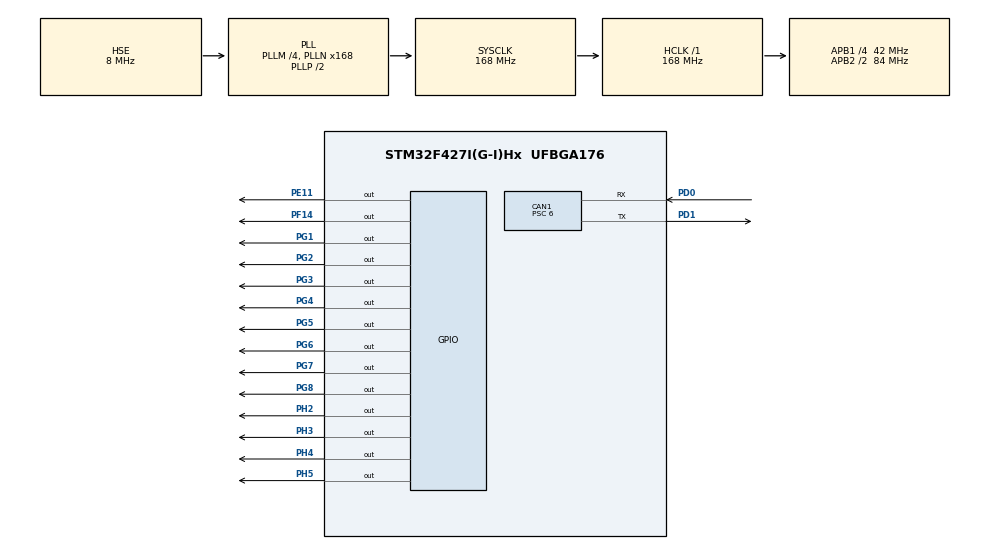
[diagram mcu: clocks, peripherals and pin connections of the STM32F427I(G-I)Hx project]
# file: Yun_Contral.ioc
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CAN1.BS1=CAN_BS1_3TQ
CAN1.BS2=CAN_BS2_3TQ
CAN1.CalculateTimeQuantum=142.85714285714286
CAN1.Prescaler=6
Mcu.Family=STM32F4
Mcu.Name=STM32F427I(G-I)Hx
Mcu.Package=UFBGA176
NVIC.CAN1_RX0_IRQn=true\:5\:0\:true\:false\:true\:true\:true
NVIC.PriorityGroup=NVIC_PRIORITYGROUP_4
PD0.Mode=Master
PD0.Signal=CAN1_RX
PD1.Mode=Master
PD1.Signal=CAN1_TX
PE11.GPIO_PuPd=GPIO_PULLUP
PE11.GPIO_Speed=GPIO_SPEED_FREQ_HIGH
PE11.PinState=GPIO_PIN_SET
PE11.Signal=GPIO_Output
PF14.GPIO_ModeDefaultOutputPP=GPIO_MODE_OUTPUT_PP
PF14.GPIO_PuPd=GPIO_PULLUP
PF14.GPIO_Speed=GPIO_SPEED_FREQ_HIGH
PF14.PinState=GPIO_PIN_SET
PF14.Signal=GPIO_Output
PG1.GPIO_ModeDefaultOutputPP=GPIO_MODE_OUTPUT_PP
PG1.GPIO_PuPd=GPIO_PULLUP
PG1.GPIO_Speed=GPIO_SPEED_FREQ_HIGH
PG1.PinState=GPIO_PIN_SET
PG1.Signal=GPIO_Output
PG2.GPIO_ModeDefaultOutputPP=GPIO_MODE_OUTPUT_PP
PG2.GPIO_PuPd=GPIO_PULLUP
PG2.GPIO_Speed=GPIO_SPEED_FREQ_HIGH
PG2.PinState=GPIO_PIN_SET
PG2.Signal=GPIO_Output
PG3.GPIO_ModeDefaultOutputPP=GPIO_MODE_OUTPUT_PP
PG3.GPIO_PuPd=GPIO_PULLUP
PG3.GPIO_Speed=GPIO_SPEED_FREQ_HIGH
PG3.PinState=GPIO_PIN_SET
PG3.Signal=GPIO_Output
PG4.GPIO_ModeDefaultOutputPP=GPIO_MODE_OUTPUT_PP
PG4.GPIO_PuPd=GPIO_PULLUP
PG4.GPIO_Speed=GPIO_SPEED_FREQ_HIGH
PG4.PinState=GPIO_PIN_SET
PG4.Signal=GPIO_Output
PG5.GPIO_ModeDefaultOutputPP=GPIO_MODE_OUTPUT_PP
PG5.GPIO_PuPd=GPIO_PULLUP
PG5.GPIO_Speed=GPIO_SPEED_FREQ_HIGH
PG5.PinState=GPIO_PIN_SET
PG5.Signal=GPIO_Output
PG6.GPIO_ModeDefaultOutputPP=GPIO_MODE_OUTPUT_PP
PG6.GPIO_PuPd=GPIO_PULLUP
PG6.GPIO_Speed=GPIO_SPEED_FREQ_HIGH
PG6.PinState=GPIO_PIN_SET
PG6.Signal=GPIO_Output
PG7.GPIO_ModeDefaultOutputPP=GPIO_MODE_OUTPUT_PP
PG7.GPIO_PuPd=GPIO_PULLUP
PG7.GPIO_Speed=GPIO_SPEED_FREQ_HIGH
PG7.PinState=GPIO_PIN_SET
PG7.Signal=GPIO_Output
PG8.GPIO_ModeDefaultOutputPP=GPIO_MODE_OUTPUT_PP
PG8.GPIO_PuPd=GPIO_PULLUP
PG8.GPIO_Speed=GPIO_SPEED_FREQ_HIGH
PG8.PinState=GPIO_PIN_SET
PG8.Signal=GPIO_Output
PH0/OSC_IN.Mode=HSE-External-Oscillator
PH0/OSC_IN.Signal=RCC_OSC_IN
PH1/OSC_OUT.Mode=HSE-External-Oscillator
PH1/OSC_OUT.Signal=RCC_OSC_OUT
PH2.GPIO_ModeDefaultOutputPP=GPIO_MODE_OUTPUT_PP
PH2.GPIO_PuPd=GPIO_PULLDOWN
PH2.GPIO_Speed=GPIO_SPEED_FREQ_HIGH
PH2.PinState=GPIO_PIN_RESET
PH2.Signal=GPIO_Output
PH3.GPIO_ModeDefaultOutputPP=GPIO_MODE_OUTPUT_PP
PH3.GPIO_PuPd=GPIO_PULLDOWN
PH3.GPIO_Speed=GPIO_SPEED_FREQ_HIGH
PH3.PinState=GPIO_PIN_RESET
PH3.Signal=GPIO_Output
PH4.GPIO_ModeDefaultOutputPP=GPIO_MODE_OUTPUT_PP
PH4.GPIO_PuPd=GPIO_PULLDOWN
PH4.GPIO_Speed=GPIO_SPEED_FREQ_HIGH
PH4.PinState=GPIO_PIN_RESET
PH4.Signal=GPIO_Output
PH5.GPIO_ModeDefaultOutputPP=GPIO_MODE_OUTPUT_PP
PH5.GPIO_PuPd=GPIO_PULLDOWN
PH5.GPIO_Speed=GPIO_SPEED_FREQ_HIGH
PH5.PinState=GPIO_PIN_RESET
PH5.Signal=GPIO_Output
ProjectManager.HeapSize=0x200
ProjectManager.StackSize=0x400
ProjectManager.TargetToolchain=MDK-ARM V5.27
RCC.48MHZClocksFreq_Value=84000000
RCC.AHBFreq_Value=168000000
RCC.APB1CLKDivider=RCC_HCLK_DIV4
RCC.APB1Freq_Value=42000000
RCC.APB1TimFreq_Value=84000000
RCC.APB2CLKDivider=RCC_HCLK_DIV2
RCC.APB2Freq_Value=84000000
RCC.APB2TimFreq_Value=168000000
RCC.CortexFreq_Value=168000000
RCC.HCLKFreq_Value=168000000
RCC.HSE_VALUE=8000000
RCC.HSI_VALUE=16000000
RCC.LSE_VALUE=32768
RCC.PLLM=4
RCC.PLLN=168
RCC.PLLSourceVirtual=RCC_PLLSOURCE_HSE
RCC.SYSCLKFreq_VALUE=168000000
RCC.SYSCLKSource=RCC_SYSCLKSOURCE_PLLCLK
RCC.VCOOutputFreq_Value=336000000
board=custom

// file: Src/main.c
/* USER CODE BEGIN Header */
/**
  ******************************************************************************
  * @file           : main.c
  * @brief          : Main program body
  ******************************************************************************
  * @attention
  *
  * <h2><center>&copy; Copyright (c) 2021 STMicroelectronics.
  * All rights reserved.</center></h2>
  *
  * This software component is licensed by ST under BSD 3-Clause license,
  * the "License"; You may not use this file except in compliance with the
  * License. You may obtain a copy of the License at:
  *                        opensource.org/licenses/BSD-3-Clause
  *
  ******************************************************************************
  */
/* USER CODE END Header */

#include "main.h"
#include "can.h"
#include "gpio.h"

void SystemClock_Config(void);

int main(void)
{

  /* MCU Configuration--------------------------------------------------------*/

  /* Reset of all peripherals, Initializes the Flash interface and the Systick. */
  HAL_Init();

  /* Configure the system clock */
  SystemClock_Config();

  /* Initialize all configured peripherals */
  MX_GPIO_Init();
  MX_CAN1_Init();
  /* USER CODE BEGIN 2 */
	Power_Init();

	CAN_FilterConfig(&hcan1);
	HAL_CAN_ActivateNotification(&hcan1,CAN_IT_RX_FIFO0_MSG_PENDING);
	HAL_CAN_Start(&hcan1);
  /* USER CODE END 2 */

  /* Infinite loop */
  while (1)
  {

  }
}

void SystemClock_Config(void)
{
  RCC_OscInitTypeDef RCC_OscInitStruct = {0};
  RCC_ClkInitTypeDef RCC_ClkInitStruct = {0};

  /** Configure the main internal regulator output voltage
  */
  __HAL_RCC_PWR_CLK_ENABLE();
  __HAL_PWR_VOLTAGESCALING_CONFIG(PWR_REGULATOR_VOLTAGE_SCALE1);
  /** Initializes the CPU, AHB and APB busses clocks
  */
  RCC_OscInitStruct.OscillatorType = RCC_OSCILLATORTYPE_HSE;
  RCC_OscInitStruct.HSEState = RCC_HSE_ON;
  RCC_OscInitStruct.PLL.PLLState = RCC_PLL_ON;
  RCC_OscInitStruct.PLL.PLLSource = RCC_PLLSOURCE_HSE;
  RCC_OscInitStruct.PLL.PLLM = 4;
  RCC_OscInitStruct.PLL.PLLN = 168;
  RCC_OscInitStruct.PLL.PLLP = RCC_PLLP_DIV2;
  RCC_OscInitStruct.PLL.PLLQ = 4;
  if (HAL_RCC_OscConfig(&RCC_OscInitStruct) != HAL_OK)
  {
    Error_Handler();
  }
  /** Initializes the CPU, AHB and APB busses clocks
  */
  RCC_ClkInitStruct.ClockType = RCC_CLOCKTYPE_HCLK|RCC_CLOCKTYPE_SYSCLK
                              |RCC_CLOCKTYPE_PCLK1|RCC_CLOCKTYPE_PCLK2;
  RCC_ClkInitStruct.SYSCLKSource = RCC_SYSCLKSOURCE_PLLCLK;
  RCC_ClkInitStruct.AHBCLKDivider = RCC_SYSCLK_DIV1;
  RCC_ClkInitStruct.APB1CLKDivider = RCC_HCLK_DIV4;
  RCC_ClkInitStruct.APB2CLKDivider = RCC_HCLK_DIV2;

  if (HAL_RCC_ClockConfig(&RCC_ClkInitStruct, FLASH_LATENCY_5) != HAL_OK)
  {
    Error_Handler();
  }
}

void Error_Handler(void)
{
}

/************************ (C) COPYRIGHT STMicroelectronics *****END OF FILE****/
